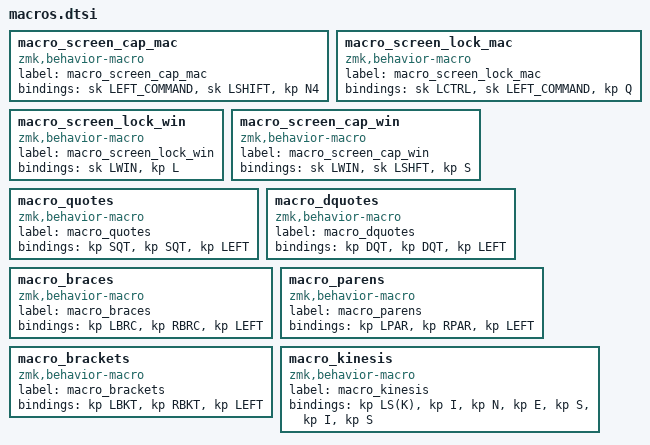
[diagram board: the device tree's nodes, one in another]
macro_screen_cap_mac: macro_screen_cap_mac{
compatible = "zmk,behavior-macro";
label = "macro_screen_cap_mac";
#binding-cells = <0>;
bindings = <&sk LEFT_COMMAND>, <&sk LSHIFT>, <&kp N4>;
};
macro_screen_lock_mac: macro_screen_lock_mac{
compatible = "zmk,behavior-macro";
label = "macro_screen_lock_mac";
#binding-cells = <0>;
bindings = <&sk LCTRL>, <&sk LEFT_COMMAND>, <&kp Q>;
};
macro_screen_lock_win: macro_screen_lock_win{
compatible = "zmk,behavior-macro";
label = "macro_screen_lock_win";
#binding-cells = <0>;
bindings = <&sk LWIN>, <&kp L>;
};
macro_screen_cap_win: macro_screen_cap_win{
compatible = "zmk,behavior-macro";
label = "macro_screen_cap_win";
#binding-cells = <0>;
bindings = <&sk LWIN>, <&sk LSHFT>, <&kp S>;
};
macro_quotes: macro_quotes{
compatible = "zmk,behavior-macro";
label = "macro_quotes";
#binding-cells = <0>;
bindings = <&kp SQT>, <&kp SQT>, <&kp LEFT>;
};
macro_dquotes: macro_dquotes{
compatible = "zmk,behavior-macro";
label = "macro_dquotes";
#binding-cells = <0>;
bindings = <&kp DQT>, <&kp DQT>, <&kp LEFT>;
};
macro_braces: macro_braces{
compatible = "zmk,behavior-macro";
label = "macro_braces";
#binding-cells = <0>;
bindings = <&kp LBRC>, <&kp RBRC>, <&kp LEFT>;
};
macro_parens: macro_parens{
compatible = "zmk,behavior-macro";
label = "macro_parens";
#binding-cells = <0>;
bindings = <&kp LPAR>, <&kp RPAR>, <&kp LEFT>;
};
macro_brackets: macro_brackets{
compatible = "zmk,behavior-macro";
label = "macro_brackets";
#binding-cells = <0>;
bindings = <&kp LBKT>, <&kp RBKT>, <&kp LEFT>;
};
macro_kinesis: macro_kinesis{
compatible = "zmk,behavior-macro";
label = "macro_kinesis";
#binding-cells = <0>;
bindings = <&kp LS(K)>, <&kp I>, <&kp N>, <&kp E>, <&kp S>, <&kp I>, <&kp S>;
};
